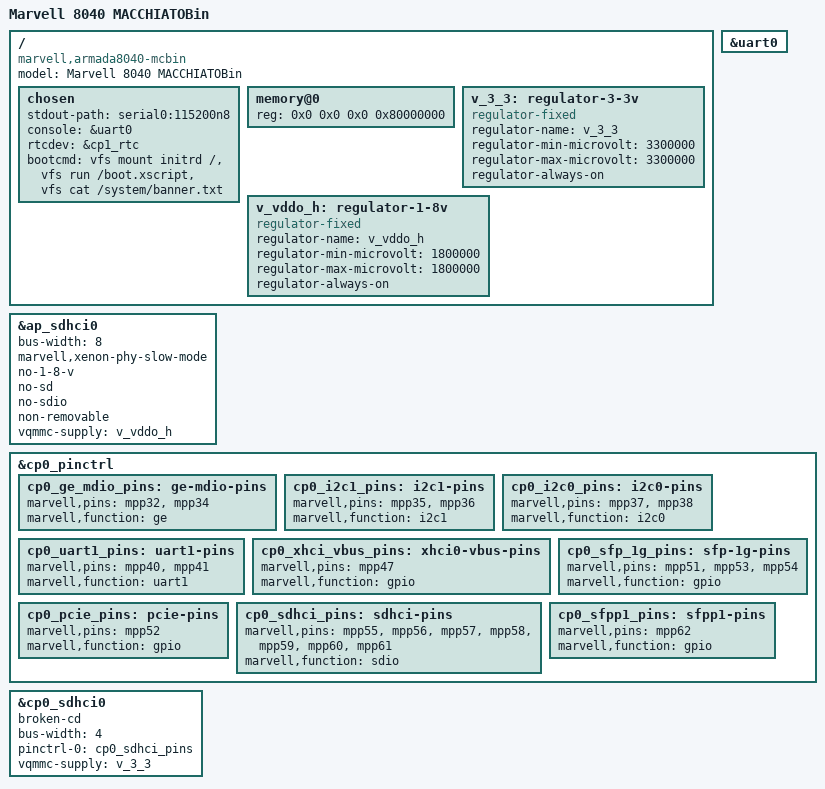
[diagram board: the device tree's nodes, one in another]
// SPDX-License-Identifier: (GPL-2.0+ OR MIT)
/*
 * Copyright (C) 2016 Marvell Technology Group Ltd.
 *
 * Device Tree file for MACCHIATOBin Armada 8040 community board platform
 */

#include "armada-8040.dtsi"

/ {
	model = "Marvell 8040 MACCHIATOBin";
	compatible = "marvell,armada8040-mcbin", "marvell,armada8040",
			"marvell,armada-ap806-quad", "marvell,armada-ap806";

	chosen {
		stdout-path = "serial0:115200n8";
		console = &uart0;
		rtcdev = &cp1_rtc;
		bootcmd = /* Mount initrd device */
			  "vfs mount initrd /",

			  /* Run boot script */
			  "vfs run /boot.xscript",

			  /* Print banner */
			  "vfs cat /system/banner.txt";
	};

	memory@0 {
		device_type = "memory";
		reg = <0x0 0x0 0x0 0x80000000>;
	};

	/* Regulator labels correspond with schematics */
	v_3_3: regulator-3-3v {
		compatible = "regulator-fixed";
		regulator-name = "v_3_3";
		regulator-min-microvolt = <3300000>;
		regulator-max-microvolt = <3300000>;
		regulator-always-on;
		status = "okay";
	};

	v_vddo_h: regulator-1-8v {
		compatible = "regulator-fixed";
		regulator-name = "v_vddo_h";
		regulator-min-microvolt = <1800000>;
		regulator-max-microvolt = <1800000>;
		regulator-always-on;
		status = "okay";
	};
};

&uart0 {
	status = "okay";
};

&ap_sdhci0 {
	bus-width = <8>;
	/*
	 * Not stable in HS modes - phy needs "more calibration", so add
	 * the "slow-mode" and disable SDR104, SDR50 and DDR50 modes.
	 */
	marvell,xenon-phy-slow-mode;
	no-1-8-v;
	no-sd;
	no-sdio;
	non-removable;
	status = "okay";
	vqmmc-supply = <&v_vddo_h>;
};

&cp0_pinctrl {
	cp0_ge_mdio_pins: ge-mdio-pins {
		marvell,pins = "mpp32", "mpp34";
		marvell,function = "ge";
	};
	cp0_i2c1_pins: i2c1-pins {
		marvell,pins = "mpp35", "mpp36";
		marvell,function = "i2c1";
	};
	cp0_i2c0_pins: i2c0-pins {
		marvell,pins = "mpp37", "mpp38";
		marvell,function = "i2c0";
	};
	cp0_uart1_pins: uart1-pins {
		marvell,pins = "mpp40", "mpp41";
		marvell,function = "uart1";
	};
	cp0_xhci_vbus_pins: xhci0-vbus-pins {
		marvell,pins = "mpp47";
		marvell,function = "gpio";
	};
	cp0_sfp_1g_pins: sfp-1g-pins {
		marvell,pins = "mpp51", "mpp53", "mpp54";
		marvell,function = "gpio";
	};
	cp0_pcie_pins: pcie-pins {
		marvell,pins = "mpp52";
		marvell,function = "gpio";
	};
	cp0_sdhci_pins: sdhci-pins {
		marvell,pins = "mpp55", "mpp56", "mpp57", "mpp58", "mpp59",
			       "mpp60", "mpp61";
		marvell,function = "sdio";
	};
	cp0_sfpp1_pins: sfpp1-pins {
		marvell,pins = "mpp62";
		marvell,function = "gpio";
	};
};

&cp0_sdhci0 {
	/* U6 */
	broken-cd;
	bus-width = <4>;
	pinctrl-names = "default";
	pinctrl-0 = <&cp0_sdhci_pins>;
	status = "okay";
	vqmmc-supply = <&v_3_3>;
};
